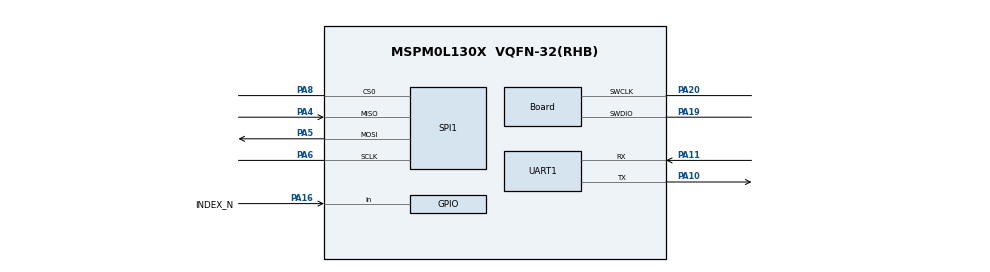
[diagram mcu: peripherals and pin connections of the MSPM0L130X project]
/**
 * @cliArgs --device "MSPM0L130X" --package "VQFN-32(RHB)" --part "Default" --product "mspm0_sdk@1.10.01.05"
 * @versions {"tool":"1.17.0+3128"}
 */

/**
 * Import the modules used in this configuration.
 */
const Board  = scripting.addModule("/ti/driverlib/Board");
const EVENT  = scripting.addModule("/ti/driverlib/EVENT");
const GPIO   = scripting.addModule("/ti/driverlib/GPIO", {}, false);
const GPIO1  = GPIO.addInstance();
const GPIO2  = GPIO.addInstance();
const GPIO3  = GPIO.addInstance();
const GPIO4  = GPIO.addInstance();
const SPI    = scripting.addModule("/ti/driverlib/SPI", {}, false);
const SPI1   = SPI.addInstance();
const SYSCTL = scripting.addModule("/ti/driverlib/SYSCTL");
const UART   = scripting.addModule("/ti/driverlib/UART", {}, false);
const UART1  = UART.addInstance();

/**
 * Write custom configuration values to the imported modules.
 */
Board.peripheral.$assign          = "DEBUGSS";
Board.peripheral.swclkPin.$assign = "PA20";
Board.peripheral.swdioPin.$assign = "PA19";

GPIO1.port                          = "PORTA";
GPIO1.$name                         = "QUAD_DECODE";
GPIO1.associatedPins.create(4);
GPIO1.associatedPins[0].direction   = "INPUT";
GPIO1.associatedPins[0].interruptEn = true;
GPIO1.associatedPins[0].polarity    = "RISE_FALL";
GPIO1.associatedPins[0].ioStructure = "SD";
GPIO1.associatedPins[0].assignedPin = "13";
GPIO1.associatedPins[0].$name       = "CMP_P1";
GPIO1.associatedPins[1].$name       = "CMP_P2";
GPIO1.associatedPins[1].direction   = "INPUT";
GPIO1.associatedPins[1].ioStructure = "SD";
GPIO1.associatedPins[1].interruptEn = true;
GPIO1.associatedPins[1].polarity    = "RISE_FALL";
GPIO1.associatedPins[1].assignedPin = "14";
GPIO1.associatedPins[2].$name       = "CMP_P3";
GPIO1.associatedPins[2].direction   = "INPUT";
GPIO1.associatedPins[2].ioStructure = "SD";
GPIO1.associatedPins[2].assignedPin = "15";
GPIO1.associatedPins[2].interruptEn = true;
GPIO1.associatedPins[2].polarity    = "RISE_FALL";
GPIO1.associatedPins[3].$name       = "INDEX_N";
GPIO1.associatedPins[3].ioStructure = "SD";
GPIO1.associatedPins[3].direction   = "INPUT";
GPIO1.associatedPins[3].assignedPin = "16";
GPIO1.associatedPins[3].interruptEn = true;
GPIO1.associatedPins[3].polarity    = "FALL";
GPIO1.associatedPins[3].pin.$assign = "PA16";

GPIO2.$name                          = "USER_INTERFACE";
GPIO2.port                           = "PORTA";
GPIO2.associatedPins.create(2);
GPIO2.associatedPins[0].assignedPin  = "0";
GPIO2.associatedPins[0].initialValue = "SET";
GPIO2.associatedPins[0].$name        = "USER_LED1";
GPIO2.associatedPins[1].assignedPin  = "1";
GPIO2.associatedPins[1].initialValue = "SET";
GPIO2.associatedPins[1].$name        = "USER_LED2";

GPIO3.$name                         = "FRAM_IO";
GPIO3.port                          = "PORTA";
GPIO3.associatedPins.create(2);
GPIO3.associatedPins[0].$name       = "FRAM_WP_N";
GPIO3.associatedPins[0].assignedPin = "3";
GPIO3.associatedPins[0].ioStructure = "SD";
GPIO3.associatedPins[1].$name       = "FRAM_HOLD_N";
GPIO3.associatedPins[1].ioStructure = "SD";
GPIO3.associatedPins[1].assignedPin = "7";

GPIO4.port                          = "PORTA";
GPIO4.$name                         = "POWER_MONITOR";
GPIO4.associatedPins[0].direction   = "INPUT";
GPIO4.associatedPins[0].assignedPin = "18";
GPIO4.associatedPins[0].$name       = "PFAIL";
GPIO4.associatedPins[0].interruptEn = true;
GPIO4.associatedPins[0].polarity    = "RISE";

SPI1.$name                              = "FRAM_SPI";
SPI1.targetBitRate                      = 16000000;
SPI1.enableDMAEvent1                    = false;
SPI1.enableDMAEvent2                    = false;
SPI1.peripheral.$assign                 = "SPI0";
SPI1.peripheral.sclkPin.$assign         = "PA6";
SPI1.peripheral.mosiPin.$assign         = "PA5";
SPI1.peripheral.misoPin.$assign         = "PA4";
SPI1.peripheral.cs0Pin.$assign          = "PA8";
SPI1.sclkPinConfig.$name                = "ti_driverlib_gpio_GPIOPinGeneric0";
SPI1.sclkPinConfig.direction            = scripting.forceWrite("OUTPUT");
SPI1.sclkPinConfig.onlyInternalResistor = scripting.forceWrite(false);
SPI1.sclkPinConfig.passedPeripheralType = scripting.forceWrite("Digital");
SPI1.mosiPinConfig.$name                = "ti_driverlib_gpio_GPIOPinGeneric1";
SPI1.mosiPinConfig.direction            = scripting.forceWrite("OUTPUT");
SPI1.mosiPinConfig.hideOutputInversion  = scripting.forceWrite(false);
SPI1.mosiPinConfig.onlyInternalResistor = scripting.forceWrite(false);
SPI1.mosiPinConfig.passedPeripheralType = scripting.forceWrite("Digital");
SPI1.misoPinConfig.$name                = "ti_driverlib_gpio_GPIOPinGeneric2";
SPI1.misoPinConfig.onlyInternalResistor = scripting.forceWrite(false);
SPI1.misoPinConfig.passedPeripheralType = scripting.forceWrite("Digital");
SPI1.cs0PinConfig.$name                 = "ti_driverlib_gpio_GPIOPinGeneric3";
SPI1.cs0PinConfig.direction             = scripting.forceWrite("OUTPUT");
SPI1.cs0PinConfig.hideOutputInversion   = scripting.forceWrite(false);
SPI1.cs0PinConfig.onlyInternalResistor  = scripting.forceWrite(false);
SPI1.cs0PinConfig.passedPeripheralType  = scripting.forceWrite("Digital");

SYSCTL.clockTreeEn = true;

UART1.targetBaudRate                   = 115200;
UART1.$name                            = "UART_1";
UART1.peripheral.$assign               = "UART1";
UART1.peripheral.rxPin.$assign         = "PA11";
UART1.peripheral.txPin.$assign         = "PA10";
UART1.txPinConfig.$name                = "ti_driverlib_gpio_GPIOPinGeneric4";
UART1.txPinConfig.direction            = scripting.forceWrite("OUTPUT");
UART1.txPinConfig.hideOutputInversion  = scripting.forceWrite(false);
UART1.txPinConfig.onlyInternalResistor = scripting.forceWrite(false);
UART1.txPinConfig.passedPeripheralType = scripting.forceWrite("Digital");
UART1.rxPinConfig.$name                = "ti_driverlib_gpio_GPIOPinGeneric5";
UART1.rxPinConfig.hideOutputInversion  = scripting.forceWrite(false);
UART1.rxPinConfig.onlyInternalResistor = scripting.forceWrite(false);
UART1.rxPinConfig.passedPeripheralType = scripting.forceWrite("Digital");

/**
 * Pinmux solution for unlocked pins/peripherals. This ensures that minor changes to the automatic solver in a future
 * version of the tool will not impact the pinmux you originally saw.  These lines can be completely deleted in order to
 * re-solve from scratch.
 */
GPIO1.associatedPins[0].pin.$suggestSolution = "PA13";
GPIO1.associatedPins[1].pin.$suggestSolution = "PA14";
GPIO1.associatedPins[2].pin.$suggestSolution = "PA15";
GPIO2.associatedPins[0].pin.$suggestSolution = "PA0";
GPIO2.associatedPins[1].pin.$suggestSolution = "PA1";
GPIO3.associatedPins[0].pin.$suggestSolution = "PA3";
GPIO3.associatedPins[1].pin.$suggestSolution = "PA7";
GPIO4.associatedPins[0].pin.$suggestSolution = "PA18";
